# SPC1169 register map
File version: 2022071043481212
CPU: cm4 r1p0, little endian, no MPU, FPU, 4 interrupt priority bits
Registers are 32-bit, read-write, reset 0x0 unless marked. A register's access mark holds for its fields unless they carry their own. Offsets are from the block's base; [hi:lo] are bit positions; 'fields as' and 'values as' point back to an identical list.

## CRC
Base 0x40003600
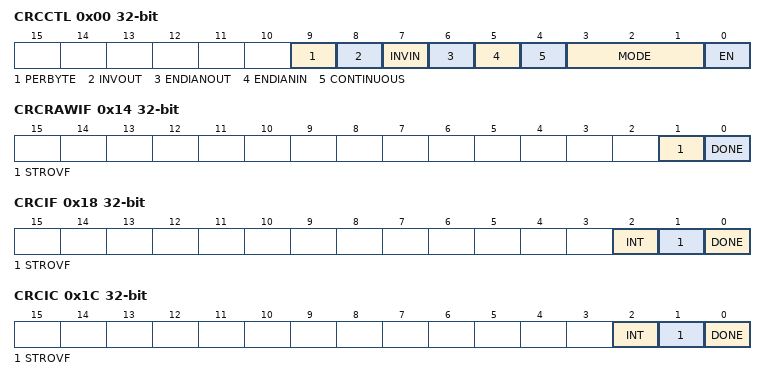
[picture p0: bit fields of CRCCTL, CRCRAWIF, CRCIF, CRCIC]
0x00 CRCCTL — CRC Control Register
  [9] PERBYTE — Set the data format for each write to the CRCSTRIN register
    0=PER_WORD (CRCSTRIN is written per word (4 bytes)); 1=PER_BYTE (CRCSTRIN is written per byte)
  [8] INVOUT — Bitwise NOT of the output result
    0=DISABLE (Output result is the original value in LFSR); 1=ENABLE (Output result is the bitwise NOT of value in LFSR)
  [7] INVIN — Bitwise NOT of the input data
    0=DISABLE (Put the original data into LFSR); 1=ENABLE (Put the bitwise NOT of the data into LFSR)
  [6] ENDIANOUT — Output result endian
    0=LITTLE_ENDIAN (LSB is last stage in LFSR); 1=BIG_ENDIAN (LSB is first stage in LFSR)
  [5] ENDIANIN — Input data endian (per byte)
    0=LITTLE_ENDIAN (LSB is firstly sent into the LFSR per byte); 1=BIG_ENDIAN (MSB is firstly sent into the LFSR per byte)
  [4] CONTINUOUS — Continuous frame calculation
    0=DISABLE (Internal register will be cleared when CRCCTL.EN=0 so next frame calculation is a fresh new start); 1=ENABLE (Internal register hold the value when CRCCTL.EN=0 so next frame calculation is continous to current one)
  [3:1] MODE — CRC mode select
    0=8_AUTOSAR (x^8+x^5+x^3+x^2+x+1); 1=15_CAN (x^15+x^14+x^10+x^8+x^7+x^4+x^3+1 (CRC-15-CAN)); 2=16_CCITT (x^16+x^12+x^5+1 (CRC-16-CCITT)); 3=16_IBM (x^16+x^15+x^2+1 (CRC-16-IBM)); 4=16_T10_DIF (x^16+x^15+x^11+x^9+x^8+x^7+x^5+x^4+x^2+x+1 (CRC-16-T10-DIF)); 5=16_DNP (x^16+x^13+x^12+x^11+x^10+x^8+x^6+x^5+x^2+1(CRC-16-DNP)); 6=17_CAN (x^17+x^16+x^14+x^13+x^11+x^6+x^4+x^3+x+1 (CRC-17-CAN)); 7=32_IEEE802P3 (x^32+x^26+x^23+x^22+x^16+x^12+x^11+x^10+x^8+x^7+x^5+x^4+x^2+x+1 (CRC-32-IEEE802.3))
  [0] EN — CRC calculate enable
    0=DISABLE (Disable CRC calculation); 1=ENABLE (Enable CRC calculation)
0x04 CRCSTRLEN — CRC Stream Length Register
  [31:0] VAL — Input stream length minus 1 (in unit of byte)
0x08 CRCSEED
  [31:0] VAL — Set the LFSR values to the seed
0x0C CRCSTRIN — CRC Stream Input Register
  [31:0] VAL — Stream Input data register. The 24 MSBs will be always read as 0 if CRCCTLEN.PERBYTE=1
0x10 CRCRESULT ro
  [31:0] VAL — CRC calculation result
0x14 CRCRAWIF ro — CRC Raw Interrupt Flag Register
  [1] STROVF — Unmasked CRC stream overflow interrupt flag
    0=NOT_OCCUR (Input stream does not overflow); 1=OCCUR (Input stream exceeds the specified length)
  [0] DONE — Unmasked CRC calculation done interrupt flag
    0=NOT_OCCUR (CRC calculation is not done); 1=OCCUR (CRC calculation is done)
0x18 CRCIF ro — CRC Interrupt Flag Register
  [2] INT — Global CRC interrupt flag issued to CPU
    0=NOT_OCCUR (No interrupt was issued to CPU); 1=OCCUR (Interrupt was issued to CPU. Further interrupt will not be generated until this bit is cleared)
  [1] STROVF — Masked CRC stream overflow interrupt flag
    0=NOT_OCCUR (Interrupt does not occur); 1=OCCUR (Interrupt occurred. Further event will not generate interrupt until this bit is cleared.)
  [0] DONE — Masked CRC calculation done interrupt flag
    values as STROVF
0x1C CRCIC — CRC Interrupt Clear Register
  [2] INT — Global CRC interrupt clear
    0=NO_EFFECT (Write a 0 has no effect and always reads back 0); 1=CLEAR (Write a 1 clears both CRCIF.INT. This bit is self-cleared to 0)
  [1] STROVF — CRC stream overflow interrupt clear
    0=NO_EFFECT (Write a 0 has no effect and always reads back 0); 1=CLEAR (Write a 1 clears STROVF bit in both CRCRAWIF and CRCIF. This bit is self-cleared to 0)
  [0] DONE — CRC calculation done interrupt clear
    0=NO_EFFECT (Write a 0 has no effect and always reads back 0); 1=CLEAR (Write a 1 clears DONE bit in both CRCRAWIF and CRCIF. This bit is self-cleared to 0)
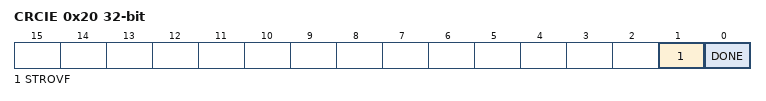
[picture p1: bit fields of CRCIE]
0x20 CRCIE — CRC Interrupt Enable Register
  [1] STROVF — CRC stream overflow interrupt enable
    0=DISABLE; 1=ENABLE
  [0] DONE — CRC calculation done interrupt enable
    0=DISABLE; 1=ENABLE
0x24 CRCREGKEY reset 0x1ACCE551 — CRC Register Write-Allow Key Register
  [31:0] KEY — Write 0x1ACCE551 to unlock protected CRC registers
